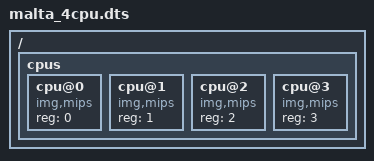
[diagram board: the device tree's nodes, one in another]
/dts-v1/;

/include/ "dts/malta.dtsi"

/ {
    cpus {
        #address-cells = <1>;
        #size-cells = <0>;

        cpu@0 {
            device_type = "cpu";
            compatible = "img,mips";
            reg = <0>;
        };

        cpu@1 {
            device_type = "cpu";
            compatible = "img,mips";
            reg = <1>;
        };

        cpu@2 {
            device_type = "cpu";
            compatible = "img,mips";
            reg = <2>;
        };

        cpu@3 {
            device_type = "cpu";
            compatible = "img,mips";
            reg = <3>;
        };
    };
};
